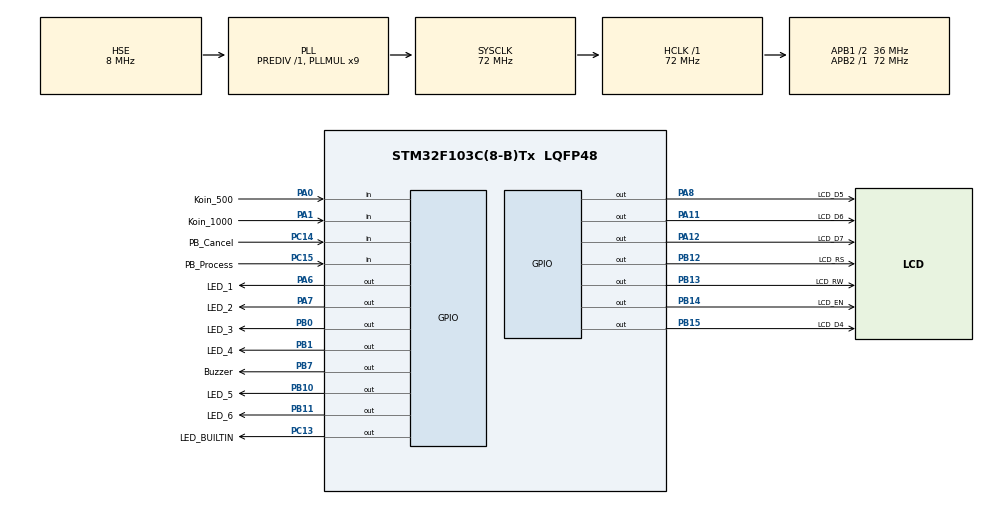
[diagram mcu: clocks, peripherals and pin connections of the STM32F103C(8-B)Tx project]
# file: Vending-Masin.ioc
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Mcu.Family=STM32F1
Mcu.Name=STM32F103C(8-B)Tx
Mcu.Package=LQFP48
NVIC.PriorityGroup=NVIC_PRIORITYGROUP_4
NVIC.TIM2_IRQn=true\:0\:0\:false\:false\:true\:true\:true
PA0-WKUP.GPIO_Label=Koin_500
PA0-WKUP.GPIO_PuPd=GPIO_PULLUP
PA0-WKUP.Signal=GPIO_Input
PA1.GPIO_Label=Koin_1000
PA1.GPIO_PuPd=GPIO_PULLUP
PA1.Signal=GPIO_Input
PA11.GPIO_Label=LCD_D6
PA11.Signal=GPIO_Output
PA12.GPIO_Label=LCD_D7
PA12.Signal=GPIO_Output
PA13.Mode=Serial_Wire
PA13.Signal=SYS_JTMS-SWDIO
PA14.Mode=Serial_Wire
PA14.Signal=SYS_JTCK-SWCLK
PA6.GPIO_Label=LED_1
PA6.Signal=GPIO_Output
PA7.GPIO_Label=LED_2
PA7.Signal=GPIO_Output
PA8.GPIO_Label=LCD_D5
PA8.Signal=GPIO_Output
PB0.GPIO_Label=LED_3
PB0.Signal=GPIO_Output
PB1.GPIO_Label=LED_4
PB1.Signal=GPIO_Output
PB10.GPIO_Label=LED_5
PB10.Signal=GPIO_Output
PB11.GPIO_Label=LED_6
PB11.Signal=GPIO_Output
PB12.GPIO_Label=LCD_RS
PB12.Signal=GPIO_Output
PB13.GPIO_Label=LCD_RW
PB13.Signal=GPIO_Output
PB14.GPIO_Label=LCD_EN
PB14.Signal=GPIO_Output
PB15.GPIO_Label=LCD_D4
PB15.Signal=GPIO_Output
PB7.GPIO_Label=Buzzer
PB7.Signal=GPIO_Output
PC13-TAMPER-RTC.GPIO_Label=LED_BUILTIN
PC13-TAMPER-RTC.Signal=GPIO_Output
PC14-OSC32_IN.GPIO_Label=PB_Cancel
PC14-OSC32_IN.GPIO_PuPd=GPIO_PULLUP
PC14-OSC32_IN.Signal=GPIO_Input
PC15-OSC32_OUT.GPIO_Label=PB_Process
PC15-OSC32_OUT.GPIO_PuPd=GPIO_PULLUP
PC15-OSC32_OUT.Signal=GPIO_Input
PD0-OSC_IN.Mode=HSE-External-Oscillator
PD0-OSC_IN.Signal=RCC_OSC_IN
PD1-OSC_OUT.Mode=HSE-External-Oscillator
PD1-OSC_OUT.Signal=RCC_OSC_OUT
ProjectManager.HeapSize=0x200
ProjectManager.StackSize=0x400
ProjectManager.TargetToolchain=STM32CubeIDE
RCC.AHBFreq_Value=72000000
RCC.APB1CLKDivider=RCC_HCLK_DIV2
RCC.APB1Freq_Value=36000000
RCC.APB1TimFreq_Value=72000000
RCC.APB2Freq_Value=72000000
RCC.APB2TimFreq_Value=72000000
RCC.HCLKFreq_Value=72000000
RCC.PLLMUL=RCC_PLL_MUL9
RCC.PLLSourceVirtual=RCC_PLLSOURCE_HSE
RCC.SYSCLKFreq_VALUE=72000000
RCC.SYSCLKSource=RCC_SYSCLKSOURCE_PLLCLK
RCC.USBFreq_Value=72000000
TIM2.Period=2000-1
TIM2.Prescaler=35999
VP_TIM2_VS_ClockSourceINT.Mode=Internal
board=custom

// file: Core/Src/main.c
/* USER CODE BEGIN Header */
/**
  ******************************************************************************
  * @file           : main.c
  * @brief          : Main program body
  ******************************************************************************
  * @attention
  *
  * <h2><center>&copy; Copyright (c) 2019 STMicroelectronics.
  * All rights reserved.</center></h2>
  *
  * This software component is licensed by ST under BSD 3-Clause license,
  * the "License"; You may not use this file except in compliance with the
  * License. You may obtain a copy of the License at:
  *                        opensource.org/licenses/BSD-3-Clause
  *
  ******************************************************************************
  */
/* USER CODE END Header */

#include "main.h"
#include "LCD.h"
#include "task.h"

TIM_HandleTypeDef htim2;

void SystemClock_Config(void);
static void MX_GPIO_Init(void);
static void MX_TIM2_Init(void);

int main(void)
{

  /* MCU Configuration--------------------------------------------------------*/

  /* Reset of all peripherals, Initializes the Flash interface and the Systick. */
  HAL_Init();

  /* Configure the system clock */
  SystemClock_Config();

  /* Initialize all configured peripherals */
  MX_GPIO_Init();
  MX_TIM2_Init();
  /* USER CODE BEGIN 2 */
  LCD_Init();
  HAL_Delay(10);
//  LCD_SetCursor(0,0);
//  LCD_Print("**VENDING  MACHINE**");
//  LCD_SetCursor(0, 1);
//  LCD_Print("    by Lapitech     ");
  task_init();
  HAL_TIM_Base_Start_IT(&htim2);
//  LCD_Clear();
  /* USER CODE END 2 */

  /* Infinite loop */
  while (1)
  {

  }
}

void SystemClock_Config(void)
{
  RCC_OscInitTypeDef RCC_OscInitStruct = {0};
  RCC_ClkInitTypeDef RCC_ClkInitStruct = {0};

  /** Initializes the CPU, AHB and APB busses clocks
  */
  RCC_OscInitStruct.OscillatorType = RCC_OSCILLATORTYPE_HSE;
  RCC_OscInitStruct.HSEState = RCC_HSE_ON;
  RCC_OscInitStruct.HSEPredivValue = RCC_HSE_PREDIV_DIV1;
  RCC_OscInitStruct.HSIState = RCC_HSI_ON;
  RCC_OscInitStruct.PLL.PLLState = RCC_PLL_ON;
  RCC_OscInitStruct.PLL.PLLSource = RCC_PLLSOURCE_HSE;
  RCC_OscInitStruct.PLL.PLLMUL = RCC_PLL_MUL9;
  if (HAL_RCC_OscConfig(&RCC_OscInitStruct) != HAL_OK)
  {
    Error_Handler();
  }
  /** Initializes the CPU, AHB and APB busses clocks
  */
  RCC_ClkInitStruct.ClockType = RCC_CLOCKTYPE_HCLK|RCC_CLOCKTYPE_SYSCLK
                              |RCC_CLOCKTYPE_PCLK1|RCC_CLOCKTYPE_PCLK2;
  RCC_ClkInitStruct.SYSCLKSource = RCC_SYSCLKSOURCE_PLLCLK;
  RCC_ClkInitStruct.AHBCLKDivider = RCC_SYSCLK_DIV1;
  RCC_ClkInitStruct.APB1CLKDivider = RCC_HCLK_DIV2;
  RCC_ClkInitStruct.APB2CLKDivider = RCC_HCLK_DIV1;

  if (HAL_RCC_ClockConfig(&RCC_ClkInitStruct, FLASH_LATENCY_2) != HAL_OK)
  {
    Error_Handler();
  }
}

static void MX_TIM2_Init(void)
{

  TIM_ClockConfigTypeDef sClockSourceConfig = {0};
  TIM_MasterConfigTypeDef sMasterConfig = {0};

  htim2.Instance = TIM2;
  htim2.Init.Prescaler = 35999;
  htim2.Init.CounterMode = TIM_COUNTERMODE_UP;
  htim2.Init.Period = 6-1;
  htim2.Init.ClockDivision = TIM_CLOCKDIVISION_DIV1;
  htim2.Init.AutoReloadPreload = TIM_AUTORELOAD_PRELOAD_DISABLE;
  if (HAL_TIM_Base_Init(&htim2) != HAL_OK)
  {
    Error_Handler();
  }
  sClockSourceConfig.ClockSource = TIM_CLOCKSOURCE_INTERNAL;
  if (HAL_TIM_ConfigClockSource(&htim2, &sClockSourceConfig) != HAL_OK)
  {
    Error_Handler();
  }
  sMasterConfig.MasterOutputTrigger = TIM_TRGO_RESET;
  sMasterConfig.MasterSlaveMode = TIM_MASTERSLAVEMODE_DISABLE;
  if (HAL_TIMEx_MasterConfigSynchronization(&htim2, &sMasterConfig) != HAL_OK)
  {
    Error_Handler();
  }

}

static void MX_GPIO_Init(void)
{
  GPIO_InitTypeDef GPIO_InitStruct = {0};

  /* GPIO Ports Clock Enable */
  __HAL_RCC_GPIOC_CLK_ENABLE();
  __HAL_RCC_GPIOD_CLK_ENABLE();
  __HAL_RCC_GPIOA_CLK_ENABLE();
  __HAL_RCC_GPIOB_CLK_ENABLE();

  /*Configure GPIO pin Output Level */
  HAL_GPIO_WritePin(LED_BUILTIN_GPIO_Port, LED_BUILTIN_Pin, GPIO_PIN_RESET);

  /*Configure GPIO pin Output Level */
  HAL_GPIO_WritePin(GPIOA, LED_1_Pin|LED_2_Pin|LCD_D5_Pin|LCD_D6_Pin
                          |LCD_D7_Pin, GPIO_PIN_RESET);

  /*Configure GPIO pin Output Level */
  HAL_GPIO_WritePin(GPIOB, LED_3_Pin|LED_4_Pin|LED_5_Pin|LED_6_Pin
                          |LCD_RS_Pin|LCD_RW_Pin|LCD_EN_Pin|LCD_D4_Pin
                          |Buzzer_Pin, GPIO_PIN_RESET);

  /*Configure GPIO pin : LED_BUILTIN_Pin */
  GPIO_InitStruct.Pin = LED_BUILTIN_Pin;
  GPIO_InitStruct.Mode = GPIO_MODE_OUTPUT_PP;
  GPIO_InitStruct.Pull = GPIO_NOPULL;
  GPIO_InitStruct.Speed = GPIO_SPEED_FREQ_LOW;
  HAL_GPIO_Init(LED_BUILTIN_GPIO_Port, &GPIO_InitStruct);

  /*Configure GPIO pins : PB_Cancel_Pin PB_Process_Pin */
  GPIO_InitStruct.Pin = PB_Cancel_Pin|PB_Process_Pin;
  GPIO_InitStruct.Mode = GPIO_MODE_INPUT;
  GPIO_InitStruct.Pull = GPIO_PULLUP;
  HAL_GPIO_Init(GPIOC, &GPIO_InitStruct);

  /*Configure GPIO pins : Koin_500_Pin Koin_1000_Pin */
  GPIO_InitStruct.Pin = Koin_500_Pin|Koin_1000_Pin;
  GPIO_InitStruct.Mode = GPIO_MODE_INPUT;
  GPIO_InitStruct.Pull = GPIO_PULLUP;
  HAL_GPIO_Init(GPIOA, &GPIO_InitStruct);

  /*Configure GPIO pins : LED_1_Pin LED_2_Pin LCD_D5_Pin LCD_D6_Pin
                           LCD_D7_Pin */
  GPIO_InitStruct.Pin = LED_1_Pin|LED_2_Pin|LCD_D5_Pin|LCD_D6_Pin
                          |LCD_D7_Pin;
  GPIO_InitStruct.Mode = GPIO_MODE_OUTPUT_PP;
  GPIO_InitStruct.Pull = GPIO_NOPULL;
  GPIO_InitStruct.Speed = GPIO_SPEED_FREQ_LOW;
  HAL_GPIO_Init(GPIOA, &GPIO_InitStruct);

  /*Configure GPIO pins : LED_3_Pin LED_4_Pin LED_5_Pin LED_6_Pin
                           LCD_RS_Pin LCD_RW_Pin LCD_EN_Pin LCD_D4_Pin
                           Buzzer_Pin */
  GPIO_InitStruct.Pin = LED_3_Pin|LED_4_Pin|LED_5_Pin|LED_6_Pin
                          |LCD_RS_Pin|LCD_RW_Pin|LCD_EN_Pin|LCD_D4_Pin
                          |Buzzer_Pin;
  GPIO_InitStruct.Mode = GPIO_MODE_OUTPUT_PP;
  GPIO_InitStruct.Pull = GPIO_NOPULL;
  GPIO_InitStruct.Speed = GPIO_SPEED_FREQ_LOW;
  HAL_GPIO_Init(GPIOB, &GPIO_InitStruct);

}

void Error_Handler(void)
{
}

/************************ (C) COPYRIGHT STMicroelectronics *****END OF FILE****/
